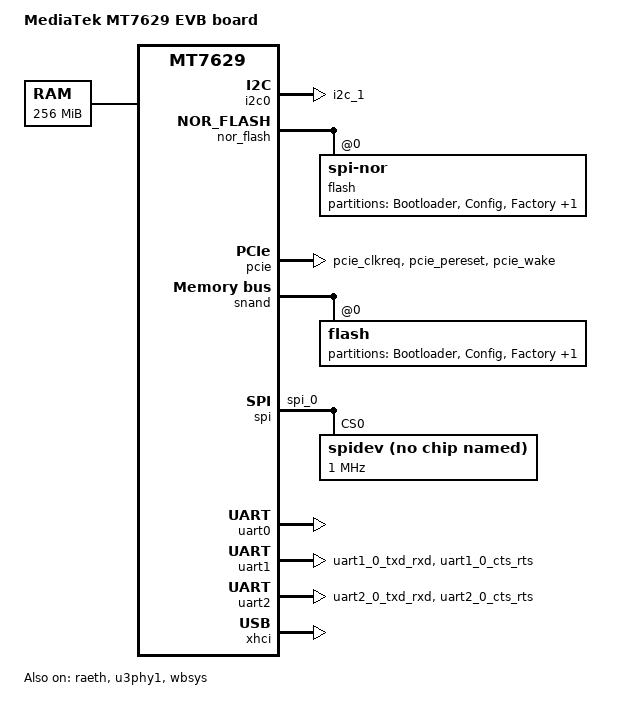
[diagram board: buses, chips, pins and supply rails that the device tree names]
/*
 * Copyright (c) 2017 MediaTek Inc.
 * Author: Dehui.Sun <dehui.sun@mediatek.com>
 *
 * This program is free software; you can redistribute it and/or modify
 * it under the terms of the GNU General Public License version 2 as
 * published by the Free Software Foundation.
 *
 * This program is distributed in the hope that it will be useful,
 * but WITHOUT ANY WARRANTY; without even the implied warranty of
 * MERCHANTABILITY or FITNESS FOR A PARTICULAR PURPOSE.  See the
 * GNU General Public License for more details.
 */

/dts-v1/;
#include "mt7629.dtsi"

/ {
	model = "MediaTek MT7629 EVB board";
	compatible = "mediatek,mt7629-evb", "mediatek,mt7629";

	chosen {
		bootargs = "earlycon=uart8250,mmio32,0x11002000 console=ttyS0,115200n1 \
loglevel=8";
	};

	memory {
		device_type = "memory";
		reg = <0 0x40000000 0 0x10000000>;
	};
};

&raeth {
	mac-address = [00 00 00 00 00 00];
	gmac1-support = "esw";
	gmac0 = "gmii";
	gmac2-support = "sgmii-2";
	sgmii-mode-2 = "force-2500";
	gmac2-force = "sgmii-switch";
	gmac1_txq_num = <1>;
	gmac1_txq_txd_num = <2048>;
	gmac2_txq_num = <1>;
	gmac2_txq_txd_num = <1024>;
	num_rx_desc = <2048>;
	status = "okay";
};

&i2c0 {
	pinctrl-names = "default";
	pinctrl-0 = <&i2c0_pins>;
};

&nor_flash {
	status = "okay";
	flash@0 {
		compatible = "jedec,spi-nor";
		#address-cells = <1>;
		#size-cells = <1>;
		partition@00000 {
			label = "Bootloader";
			reg = <0x00000 0x0060000>;
		};
		partition@60000 {
			label = "Config";
			reg = <0x60000 0x0010000>;
		};
		partition@70000 {
			label = "Factory";
			reg = <0x70000 0x0040000>;
		};
		partition@b0000 {
			label = "Kernel";
			reg = <0xb0000 0xb50000>;
		};
	};
};

&pcie {
	pinctrl-names = "default";
	pinctrl-0 = <&pinctrl_pcie_default>;
};

&pio {
	i2c0_pins: i2c0@0 {
		pins_bus {
			groups = "i2c_1";
			function = "i2c";
			bias-disable;
			drive-strength = <4>;
		};
	};

	nor_flash_pins: nor_flash_pins {
		pins_bus {
			groups = "nor_flash_io", "nor_flash_wp", "nor_flash_hold";
			function = "nor_flash";
		};
	};

	pinctrl_wifi_default: wifi-default {
		mux-wf0_5g {
			groups = "wf0_5g";
			function = "wifi";
			drive-strength = <4>;
		};
		mux-wf0_2g {
			groups = "wf0_2g";
			function = "wifi";
			drive-strength = <4>;
		};
	};

	pinctrl_pcie_default: pcie-default {
		mux-pcie_clkreq {
			groups = "pcie_clkreq";
			function = "pcie";
		};
		mux-pcie_pereset {
			groups = "pcie_pereset";
			function = "pcie";
		};
		mux-pcie_wake {
			groups = "pcie_wake";
			function = "pcie";
		};
	};

	pinctrl_snand_default: snand_default {
		pins_bus {
			groups = "snfi", "snfi_wp", "snfi_hold";
			function = "snfi";
		};
	};

	pinctrl_spi_default: spi_default {
		mux_spi {
			groups = "spi_0";
			function = "spi";
			bias-disable;
		};
	};

	uart1_pin: uart1-default {
		mux-uart {
			groups = "uart1_0_txd_rxd";
			function = "uart";
		};
		mux-flow {
			groups = "uart1_0_cts_rts";
			function = "uart";
		};
	};

	uart2_pin: uart2-default {
		mux-uart {
			groups = "uart2_0_txd_rxd";
			function = "uart";
		};
		mux-flow {
			groups = "uart2_0_cts_rts";
			function = "uart";
		};
	};
};

&snand {
	status = "okay";
	flash@0 {
		partitions {
			compatible = "fixed-partitions";
			#address-cells = <1>;
			#size-cells = <1>;

			partition@0 {
				label = "Bootloader";
				reg = <0x00000 0x0100000>;
				read-only;
			};

			partition@100000 {
				label = "Config";
				reg = <0x100000 0x0040000>;
			};

			partition@140000 {
				label = "Factory";
				reg = <0x140000 0x0080000>;
			};

			partition@1c0000 {
				label = "Kernel";
				reg = <0x1c0000 0x1000000>;
			};
		};
	};
};

&spi {
	pinctrl-names = "default";
	pinctrl-0 = <&pinctrl_spi_default>;

	spidev: spi@0 {
		compatible = "rohm,dh2228fv";
		reg = <0>;
		spi-max-frequency = <1000000>;
	};
};

&u3phy1 {
	status = "okay";
};

&uart0 {
	status = "okay";
};

&uart1 {
	pinctrl-names = "default";
	pinctrl-0 = <&uart1_pin>;
	status = "okay";
};

&uart2 {
	pinctrl-names = "default";
	pinctrl-0 = <&uart2_pin>;
	status = "okay";
};

&wbsys {
	pinctrl-names = "default";
	pinctrl-0 = <&pinctrl_wifi_default>;
	status = "okay";
};

&xhci {
	status = "okay";
};
